AUTOSAR XML (schema 4-2-2)
package /Company/Components
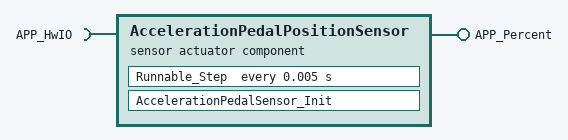
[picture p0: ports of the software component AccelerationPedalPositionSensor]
  sensor actuator sw component type AccelerationPedalPositionSensor
    require port APP_HwIO: nonqueued-receiver-com-spec{data-element=Value, init-value=ComSpec9b2b5712_628d727ad83ff330:0}, required-interface=APP_HwIO
    provide port APP_Percent: nonqueued-sender-com-spec{data-element=Value, init-value=ComSpec74722cdc_3dd1b85dd6419d3b:0}, provided-interface=APP_Percent
    behavior AccelerationPedalPositionSensor_InternalBehavior: data-type-mapping=AccelerationPedalPositionSensorDataTypeMappingsSet, handle-termination-and-restart=NO-SUPPORT
      init event AccelerationPedalSensor_InitEvent: start-on-event=AccelerationPedalSensor_Init
      timing event Event_Runnable_Step: start-on-event=Runnable_Step, period=0.005
      runnable AccelerationPedalSensor_Init
      runnable Runnable_Step
        data-read-access:
          access IN_APP_HwIO_Value: accessed-variable=APP_HwIO.Value
        data-write-access:
          access OUT_APP_Percent_Value: accessed-variable=APP_Percent.Value
        parameter access SCALPRM_SetpointPercent_LkupTbl: accessed-parameter=SetpointPercent_LkupTbl
      shared-parameters:
        parameter data prototype SetpointPercent_LkupTbl: category=CURVE, sw-calibration-access=READ-WRITE, type=Appl_SetpointPercent_LkupTbl, init-value=constant-reference={short-label=SetpointPercent_LkupTbl, constant=SetpointPercent_LkupTbl}
